VERSION "HIPBNYYYYYYYYYYYYYYYYYYYYYYYYYYYYYYYYYYYYY/4/%%%/4/'%**4YYY///"

NS_ :

BS_:

BU_:

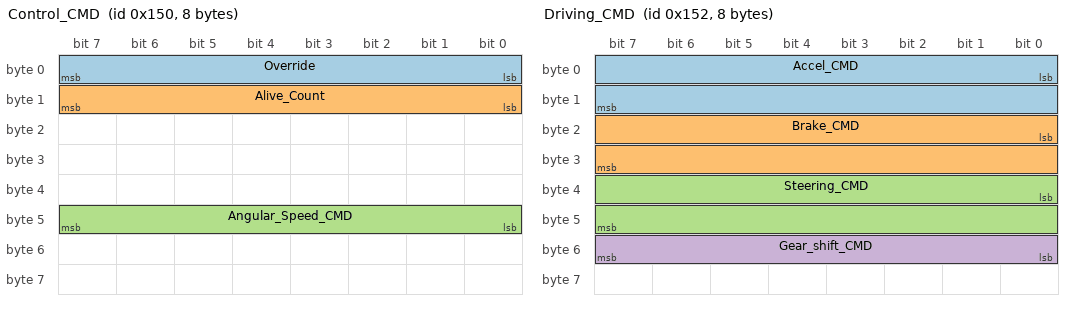
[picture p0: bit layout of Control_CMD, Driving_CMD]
BO_ 336 Control_CMD: 8 Vector__XXX
 SG_ Override : 0|8@1+ (1,0) [0|1] "" Vector__XXX
 SG_ Alive_Count : 8|8@1+ (1,0) [0|255] "" Vector__XXX
 SG_ Angular_Speed_CMD : 40|8@1+ (1,0) [0|255] "" Vector__XXX

BO_ 338 Driving_CMD: 8 Vector__XXX
 SG_ Accel_CMD : 0|16@1+ (1,0) [650|3400] "" Vector__XXX
 SG_ Brake_CMD : 16|16@1+ (1,0) [0|17000] "" Vector__XXX
 SG_ Steering_CMD : 32|16@1- (1,0) [-520|520] "deg" Vector__XXX
 SG_ Gear_shift_CMD : 48|8@1+ (1,0) [0|7] "" Vector__XXX

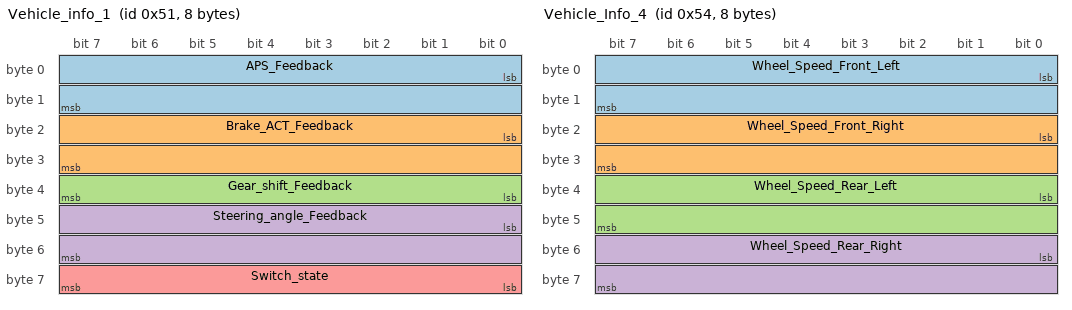
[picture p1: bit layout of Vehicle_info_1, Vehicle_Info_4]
BO_ 81 Vehicle_info_1: 8 Vector__XXX
 SG_ APS_Feedback : 0|16@1+ (1,0) [0|3800] "" Vector__XXX
 SG_ Brake_ACT_Feedback : 16|16@1+ (1,0) [0|35000] "" Vector__XXX
 SG_ Gear_shift_Feedback : 32|8@1+ (1,0) [0|7] "" Vector__XXX
 SG_ Steering_angle_Feedback : 40|16@1- (0.1,0) [-540|540] "deg" Vector__XXX
 SG_ Switch_state : 56|8@1+ (1,0) [0|0] "" Vector__XXX

BO_ 82 Vehicle_Info_2: 8 Vector__XXX
 SG_ Override_feedback : 0|8@1+ (1,0) [0|0] "" Vector__XXX
 SG_ Vehicle_Speed : 8|16@1+ (0.1,0) [0|255] "km/h" Vector__XXX

BO_ 84 Vehicle_Info_4: 8 Vector__XXX
 SG_ Wheel_Speed_Front_Left : 0|16@1+ (0.1,0) [0|255] "km/h" Vector__XXX
 SG_ Wheel_Speed_Front_Right : 16|16@1+ (0.1,0) [0|255] "km/h" Vector__XXX
 SG_ Wheel_Speed_Rear_Left : 32|16@1+ (0.1,0) [0|255] "km/h" Vector__XXX
 SG_ Wheel_Speed_Rear_Right : 48|16@1+ (0.1,0) [0|255] "km/h" Vector__XXX

BA_DEF_  "BusType" STRING ;
BA_DEF_DEF_  "BusType" "";
BA_ "BusType" "CAN";
VAL_ 336 Override 0 "Overide_On" 1 "Override_Off" ;
VAL_ 338 Gear_shift_CMD 0 "Parking" 5 "Driving" 6 "Neutral" 7 "Reverse" ;
VAL_ 81 Gear_shift_Feedback 0 "Parking" 5 "Driving" 6 "Neutral" 7 "Reverse" ;
VAL_ 81 Switch_state 0 "Manual" 1 "E-stop" 2 "Auto-standby" 4 "APM S/W On" 8 "ASM S/W On" 16 "AGM S/W On" ;
VAL_ 82 Override_feedback 0 "Manual" 1 "Auto" 2 "Steer" 3 "Accel" 4 "Brake" 5 "Sensor" 6 "E-Stop" ;
